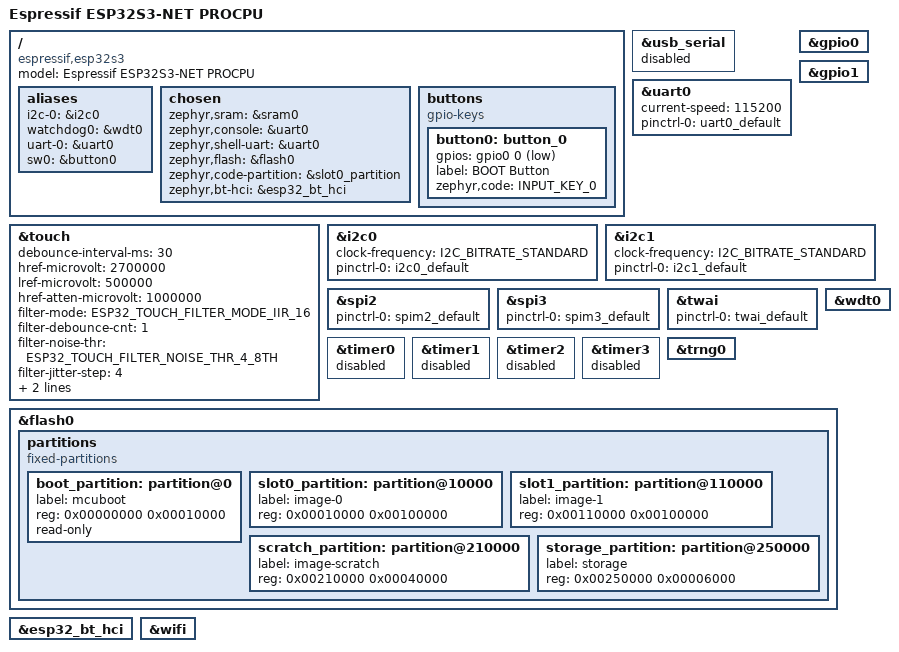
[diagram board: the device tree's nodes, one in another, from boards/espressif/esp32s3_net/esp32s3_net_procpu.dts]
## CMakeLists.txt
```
# SPDX-License-Identifier: Apache-2.0

cmake_minimum_required(VERSION 3.20.0)

list(APPEND BOARD_ROOT ${CMAKE_CURRENT_SOURCE_DIR})
find_package(Zephyr REQUIRED HINTS $ENV{ZEPHYR_BASE})

project(esp32s3_devkitc)

target_sources(app PRIVATE
	src/main.c
	src/wifi.c
	#	src/mqtt.c
	src/http.c
)
```

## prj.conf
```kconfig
CONFIG_LOG=y
CONFIG_LOG_BACKEND_UART=n
CONFIG_LOG_BUFFER_SIZE=2048

CONFIG_SHELL=y
CONFIG_SHELL_BACKEND_SERIAL=y
CONFIG_NET_L2_WIFI_SHELL=y

CONFIG_WIFI=y
CONFIG_WIFI_ESP32=y

CONFIG_NETWORKING=y
CONFIG_NET_L2_ETHERNET=y

CONFIG_NET_IPV6=n
CONFIG_NET_IPV4=y
CONFIG_NET_DHCPV4=y
CONFIG_ESP32_WIFI_STA_AUTO_DHCPV4=y
# 驱动自动重连必须关掉: 断开事件(如首次扫描 NO_AP_FOUND=201)后驱动会把
# 状态锁在 ESP32_STA_CONNECTING 并内部调用 esp_wifi_connect(), 从此应用层
# 所有连接请求都被拒绝(busy -1), 内部重连又静默卡死, 永远无法恢复。
# 关掉后驱动断开即回 ESP32_STA_STARTED, 由 wifi.c 自己的重试循环接管。
CONFIG_ESP32_WIFI_STA_RECONNECT=n
CONFIG_ESP32_WIFI_IRAM_OPT=n
CONFIG_ESP32_WIFI_RX_IRAM_OPT=n

# 网络缓冲池: 数据块必须 ≥1514(一帧一个 buffer), 否则
# 一帧要拆成 12 个 128B 碎片, 而小 RX 池连一个全尺寸帧都装不下,
# 任何 ≥1281B 的单帧(SSDP/mDNS 公告等)到达都必然报
# "Data buffer (1514) allocation failed" 丢帧 —— 不需要突发, 一帧就够
CONFIG_NET_BUF_DATA_SIZE=1600
CONFIG_NET_PKT_RX_COUNT=32
CONFIG_NET_PKT_TX_COUNT=16
CONFIG_NET_BUF_RX_COUNT=32
CONFIG_NET_BUF_TX_COUNT=16
CONFIG_NET_MAX_CONTEXTS=12
CONFIG_NET_MAX_CONN=8
CONFIG_NET_TX_STACK_SIZE=2048
CONFIG_NET_RX_STACK_SIZE=2048
# 防止扫描结果事件丢失
CONFIG_NET_MGMT_EVENT_QUEUE_SIZE=16
CONFIG_NET_MGMT_EVENT_QUEUE_TIMEOUT=5000

CONFIG_NET_LOG=y

# 堆内存大小由板级 Kconfig.defconfig 提供(esp32 wifi 需要 51200),
# 不要在这里设小值, 否则 esp_wifi_start() 内存分配失败


# ===== MQTT Configuration =====
CONFIG_NETWORKING=y
# CONFIG_MQTT_LIB=y

# MQTT 依赖 TCP 传输。Zephyr 3.7 起 NET_TCP 默认关闭且 MQTT_LIB 不会
# 自动 select, 必须显式开启, 否则 socket(SOCK_STREAM) 创建即失败,
# mqtt_connect() 报 -107 (minimal libc 中 EPROTOTYPE=107, 非 Linux 的 ENOTCONN)
CONFIG_NET_TCP=y
CONFIG_NET_SOCKETS=y
CONFIG_DNS_RESOLVER=y

# HTTP 客户端 
CONFIG_HTTP_CLIENT=y
CONFIG_POSIX_API=y
CONFIG_NET_HTTP_LOG_LEVEL_DBG=y
CONFIG_NET_SOCKETS_SOCKOPT_TLS=y
# 1. 启用安全套接字和证书
CONFIG_NET_SOCKETS_SOCKOPT_TLS=y
CONFIG_TLS_CREDENTIALS=y
# 开启 PEM 证书解析
CONFIG_MBEDTLS_PEM_CERTIFICATE_FORMAT=y
# 证书相关
# TLS configuration
CONFIG_MBEDTLS=y
CONFIG_MBEDTLS_BUILTIN=y
# CONFIG_MBEDTLS_ENABLE_HEAP=y
# CONFIG_MBEDTLS_HEAP_SIZE=32768
# 服务器的证书链握手消息约 4758 字节, 超过 4096 时 mbedTLS 3.6 在
# ssl_msg.c 报 "requesting more data than fits" → -0x7100 (BAD_INPUT_DATA)
# 握手失败。8192 足够容纳证书链和后续的响应记录。
CONFIG_MBEDTLS_SSL_MAX_CONTENT_LEN=8192

CONFIG_NET_SOCKETS_SOCKOPT_TLS=y
CONFIG_NET_SOCKETS_TLS_MAX_CONTEXTS=1
# TLS 握手在 zsock_connect() 内完成(Zephyr 3.7), 默认 3s 上限在工地
# 弱网下容易超时, 放宽到 10s
CONFIG_NET_SOCKETS_CONNECT_TIMEOUT=10000

# ========== time ===========
CONFIG_SNTP=y

# =========== PSRAM ===============
# CONFIG_ESP_SPIRAM=y
# CONFIG_SPIRAM_MODE_QUAD=y
# CONFIG_SPIRAM_TYPE_ESPPSRAM16=y
# CONFIG_SPIRAM_SPEED_40M=y
# CONFIG_ESP_SPIRAM_HEAP_SIZE=1048576
# CONFIG_ESP_HEAP_MIN_EXTRAM_THRESHOLD=2048
```

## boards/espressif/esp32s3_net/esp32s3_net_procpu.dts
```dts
/*
 * Copyright (c) 2024 Espressif Systems (Shanghai) Co., Ltd.
 *
 * SPDX-License-Identifier: Apache-2.0
 */
/dts-v1/;

#include "espressif/esp32s3/esp32s3_wroom_n8.dtsi"
#include "esp32s3_net-pinctrl.dtsi"
#include <zephyr/dt-bindings/input/input-event-codes.h>
#include <zephyr/dt-bindings/input/esp32-touch-sensor-input.h>

/ {
	model = "Espressif ESP32S3-NET PROCPU";
	compatible = "espressif,esp32s3";

	aliases {
		i2c-0 = &i2c0;
		watchdog0 = &wdt0;
	};

	chosen {
		zephyr,sram = &sram0;
		zephyr,console = &uart0;
		zephyr,shell-uart = &uart0;
		zephyr,flash = &flash0;
		zephyr,code-partition = &slot0_partition;
		zephyr,bt-hci = &esp32_bt_hci;
	};

	aliases {
		uart-0 = &uart0;
		sw0 = &button0;
	};

	buttons {
		compatible = "gpio-keys";
		button0: button_0 {
			gpios = <&gpio0 0 (GPIO_PULL_UP | GPIO_ACTIVE_LOW)>;
			label = "BOOT Button";
			zephyr,code = <INPUT_KEY_0>;
		};
	};
};

&usb_serial {
	status = "disabled";
};

&uart0 {
	status = "okay";
	current-speed = <115200>;
	pinctrl-0 = <&uart0_default>;
	pinctrl-names = "default";
};

&gpio0 {
	status = "okay";
};

&gpio1 {
	status = "okay";
};

&touch {
	debounce-interval-ms = <30>;
	href-microvolt = <2700000>;
	lref-microvolt = <500000>;
	href-atten-microvolt = <1000000>;
	filter-mode = <ESP32_TOUCH_FILTER_MODE_IIR_16>;
	filter-debounce-cnt = <1>;
	filter-noise-thr = <ESP32_TOUCH_FILTER_NOISE_THR_4_8TH>;
	filter-jitter-step = <4>;
	filter-smooth-level = <ESP32_TOUCH_FILTER_SMOOTH_MODE_IIR_2>;
};

&i2c0 {
	clock-frequency = <I2C_BITRATE_STANDARD>;
	pinctrl-0 = <&i2c0_default>;
	pinctrl-names = "default";
};

&i2c1 {
	clock-frequency = <I2C_BITRATE_STANDARD>;
	pinctrl-0 = <&i2c1_default>;
	pinctrl-names = "default";
};

&spi2 {
	#address-cells = <1>;
	#size-cells = <0>;
	status = "okay";
	pinctrl-0 = <&spim2_default>;
	pinctrl-names = "default";
};

&spi3 {
	#address-cells = <1>;
	#size-cells = <0>;
	status = "okay";
	pinctrl-0 = <&spim3_default>;
	pinctrl-names = "default";
};

&twai {
	pinctrl-0 = <&twai_default>;
	pinctrl-names = "default";
};

&timer0 {
	status = "disabled";
};

&timer1 {
	status = "disabled";
};

&timer2 {
	status = "disabled";
};

&timer3 {
	status = "disabled";
};

&wdt0 {
	status = "okay";
};

&trng0 {
	status = "okay";
};

&flash0 {
	status = "okay";
	partitions {
		compatible = "fixed-partitions";
		#address-cells = <1>;
		#size-cells = <1>;

		/* Reserve 64kB for the bootloader */
		boot_partition: partition@0 {
			label = "mcuboot";
			reg = <0x00000000 0x00010000>;
			read-only;
		};

		/* Reserve 1024kB for the application in slot 0 */
		slot0_partition: partition@10000 {
			label = "image-0";
			reg = <0x00010000 0x00100000>;
		};

		/* Reserve 1024kB for the application in slot 1 */
		slot1_partition: partition@110000 {
			label = "image-1";
			reg = <0x00110000 0x00100000>;
		};

		/* Reserve 256kB for the scratch partition */
		scratch_partition: partition@210000 {
			   label = "image-scratch";
			   reg = <0x00210000 0x00040000>;
		};

		storage_partition: partition@250000 {
			label = "storage";
			reg = <0x00250000 0x00006000>;
		};
	};
};

&esp32_bt_hci {
	status = "okay";
};

&wifi {
	status = "okay";
};
```

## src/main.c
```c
#include <zephyr/kernel.h>
#include <zephyr/logging/log.h>
#include <errno.h>

LOG_MODULE_REGISTER(main, LOG_LEVEL_INF);

int main(void)
{
	LOG_INF("This is a test.");
	while(1) {
		k_msleep(5000);
	}
}
```

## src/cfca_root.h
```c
unsigned char cfca_root_der[] = {
  0x30, 0x82, 0x05, 0x8d, 0x30, 0x82, 0x03, 0x75, 0xa0, 0x03, 0x02, 0x01,
  0x02, 0x02, 0x04, 0x18, 0x4a, 0xcc, 0xd6, 0x30, 0x0d, 0x06, 0x09, 0x2a,
  0x86, 0x48, 0x86, 0xf7, 0x0d, 0x01, 0x01, 0x0b, 0x05, 0x00, 0x30, 0x56,
  0x31, 0x0b, 0x30, 0x09, 0x06, 0x03, 0x55, 0x04, 0x06, 0x13, 0x02, 0x43,
  0x4e, 0x31, 0x30, 0x30, 0x2e, 0x06, 0x03, 0x55, 0x04, 0x0a, 0x0c, 0x27,
  0x43, 0x68, 0x69, 0x6e, 0x61, 0x20, 0x46, 0x69, 0x6e, 0x61, 0x6e, 0x63,
  0x69, 0x61, 0x6c, 0x20, 0x43, 0x65, 0x72, 0x74, 0x69, 0x66, 0x69, 0x63,
  0x61, 0x74, 0x69, 0x6f, 0x6e, 0x20, 0x41, 0x75, 0x74, 0x68, 0x6f, 0x72,
  0x69, 0x74, 0x79, 0x31, 0x15, 0x30, 0x13, 0x06, 0x03, 0x55, 0x04, 0x03,
  0x0c, 0x0c, 0x43, 0x46, 0x43, 0x41, 0x20, 0x45, 0x56, 0x20, 0x52, 0x4f,
  0x4f, 0x54, 0x30, 0x1e, 0x17, 0x0d, 0x31, 0x32, 0x30, 0x38, 0x30, 0x38,
  0x30, 0x33, 0x30, 0x37, 0x30, 0x31, 0x5a, 0x17, 0x0d, 0x32, 0x39, 0x31,
  0x32, 0x33, 0x31, 0x30, 0x33, 0x30, 0x37, 0x30, 0x31, 0x5a, 0x30, 0x56,
  0x31, 0x0b, 0x30, 0x09, 0x06, 0x03, 0x55, 0x04, 0x06, 0x13, 0x02, 0x43,
  0x4e, 0x31, 0x30, 0x30, 0x2e, 0x06, 0x03, 0x55, 0x04, 0x0a, 0x0c, 0x27,
  0x43, 0x68, 0x69, 0x6e, 0x61, 0x20, 0x46, 0x69, 0x6e, 0x61, 0x6e, 0x63,
  0x69, 0x61, 0x6c, 0x20, 0x43, 0x65, 0x72, 0x74, 0x69, 0x66, 0x69, 0x63,
  0x61, 0x74, 0x69, 0x6f, 0x6e, 0x20, 0x41, 0x75, 0x74, 0x68, 0x6f, 0x72,
  0x69, 0x74, 0x79, 0x31, 0x15, 0x30, 0x13, 0x06, 0x03, 0x55, 0x04, 0x03,
  0x0c, 0x0c, 0x43, 0x46, 0x43, 0x41, 0x20, 0x45, 0x56, 0x20, 0x52, 0x4f,
  0x4f, 0x54, 0x30, 0x82, 0x02, 0x22, 0x30, 0x0d, 0x06, 0x09, 0x2a, 0x86,
  0x48, 0x86, 0xf7, 0x0d, 0x01, 0x01, 0x01, 0x05, 0x00, 0x03, 0x82, 0x02,
  0x0f, 0x00, 0x30, 0x82, 0x02, 0x0a, 0x02, 0x82, 0x02, 0x01, 0x00, 0xd7,
  0x5d, 0x6b, 0xcd, 0x10, 0x3f, 0x1f, 0x05, 0x59, 0xd5, 0x05, 0x4d, 0x37,
  0xb1, 0x0e, 0xec, 0x98, 0x2b, 0x8e, 0x15, 0x1d, 0xfa, 0x93, 0x4b, 0x17,
  0x82, 0x21, 0x71, 0x10, 0x52, 0xd7, 0x51, 0x64, 0x70, 0x16, 0xc2, 0x55,
  0x69, 0x4d, 0x8e, 0x15, 0x6d, 0x9f, 0xbf, 0x0c, 0x1b, 0xc2, 0xe0, 0xa3,
  0x67, 0xd6, 0x0c, 0xac, 0xcf, 0x22, 0xae, 0xaf, 0x77, 0x54, 0x2a, 0x4b,
  0x4c, 0x8a, 0x53, 0x52, 0x7a, 0xc3, 0xee, 0x2e, 0xde, 0xb3, 0x71, 0x25,
  0xc1, 0xe9, 0x5d, 0x3d, 0xee, 0xa1, 0x2f, 0xa3, 0xf7, 0x2a, 0x3c, 0xc9,
  0x23, 0x1d, 0x6a, 0xab, 0x1d, 0xa1, 0xa7, 0xf1, 0xf3, 0xec, 0xa0, 0xd5,
  0x44, 0xcf, 0x15, 0xcf, 0x72, 0x2f, 0x1d, 0x63, 0x97, 0xe8, 0x99, 0xf9,
  0xfd, 0x93, 0xa4, 0x54, 0x80, 0x4c, 0x52, 0xd4, 0x52, 0xab, 0x2e, 0x49,
  0xdf, 0x90, 0xcd, 0xb8, 0x5f, 0xbe, 0x3f, 0xde, 0xa1, 0xca, 0x4d, 0x20,
  0xd4, 0x25, 0xe8, 0x84, 0x29, 0x53, 0xb7, 0xb1, 0x88, 0x1f, 0xff, 0xfa,
  0xda, 0x90, 0x9f, 0x0a, 0xa9, 0x2d, 0x41, 0x3f, 0xb1, 0xf1, 0x18, 0x29,
  0xee, 0x16, 0x59, 0x2c, 0x34, 0x49, 0x1a, 0xa8, 0x06, 0xd7, 0xa8, 0x88,
  0xd2, 0x03, 0x72, 0x7a, 0x32, 0xe2, 0xea, 0x68, 0x4d, 0x6e, 0x2c, 0x96,
  0x65, 0x7b, 0xca, 0x59, 0xfa, 0xf2, 0xe2, 0xdd, 0xee, 0x30, 0x2c, 0xfb,
  0xcc, 0x46, 0xac, 0xc4, 0x63, 0xeb, 0x6f, 0x7f, 0x36, 0x2b, 0x34, 0x73,
  0x12, 0x94, 0x7f, 0xdf, 0xcc, 0x26, 0x9e, 0xf1, 0x72, 0x5d, 0x50, 0x65,
  0x59, 0x8f, 0x69, 0xb3, 0x87, 0x5e, 0x32, 0x6f, 0xc3, 0x18, 0x8a, 0xb5,
  0x95, 0x8f, 0xb0, 0x7a, 0x37, 0xde, 0x5a, 0x45, 0x3b, 0xc7, 0x36, 0xe1,
  0xef, 0x67, 0xd1, 0x39, 0xd3, 0x97, 0x5b, 0x73, 0x62, 0x19, 0x48, 0x2d,
  0x87, 0x1c, 0x06, 0xfb, 0x74, 0x98, 0x20, 0x49, 0x73, 0xf0, 0x05, 0xd2,
  0x1b, 0xb1, 0xa0, 0xa3, 0xb7, 0x1b, 0x70, 0xd3, 0x88, 0x69, 0xb9, 0x5a,
  0xd6, 0x38, 0xf4, 0x62, 0xdc, 0x25, 0x8b, 0x78, 0xbf, 0xf8, 0xe8, 0x7e,
  0xb8, 0x5c, 0xc9, 0x95, 0x4f, 0x5f, 0xa7, 0x2d, 0xb9, 0x20, 0x6b, 0xcf,
  0x6b, 0xdd, 0xf5, 0x0d, 0xf4, 0x82, 0xb7, 0xf4, 0xb2, 0x66, 0x2e, 0x10,
  0x28, 0xf6, 0x97, 0x5a, 0x7b, 0x96, 0x16, 0x8f, 0x01, 0x19, 0x2d, 0x6c,
  0x6e, 0x7f, 0x39, 0x58, 0x06, 0x64, 0x83, 0x01, 0x83, 0x83, 0xc3, 0x4d,
  0x92, 0xdd, 0x32, 0xc6, 0x87, 0xa4, 0x37, 0xe9, 0x16, 0xce, 0xaa, 0x2d,
  0x68, 0xaf, 0x0a, 0x81, 0x65, 0x3a, 0x70, 0xc1, 0x9b, 0xad, 0x4d, 0x6d,
  0x54, 0xca, 0x2a, 0x2d, 0x4b, 0x85, 0x1b, 0xb3, 0x80, 0xe6, 0x70, 0x45,
  0x0d, 0x6b, 0x5e, 0x35, 0xf0, 0x7f, 0x3b, 0xb8, 0x9c, 0xe4, 0x04, 0x70,
  0x89, 0x12, 0x25, 0x93, 0xda, 0x0a, 0x99, 0x22, 0x60, 0x6a, 0x63, 0x60,
  0x4e, 0x76, 0x06, 0x98, 0x4e, 0xbd, 0x83, 0xad, 0x1d, 0x58, 0x8a, 0x25,
  0x85, 0xd2, 0xc7, 0x65, 0x1e, 0x2d, 0x8e, 0xc6, 0xdf, 0xb6, 0xc6, 0xe1,
  0x7f, 0x8a, 0x04, 0x21, 0x15, 0x29, 0x74, 0xf0, 0x3e, 0x9c, 0x90, 0x9d,
  0x0c, 0x2e, 0xf1, 0x8a, 0x3e, 0x5a, 0xaa, 0x0c, 0x09, 0x1e, 0xc7, 0xd5,
  0x3c, 0xa3, 0xed, 0x97, 0xc3, 0x1e, 0x34, 0xfa, 0x38, 0xf9, 0x08, 0x0e,
  0xe3, 0xc0, 0x5d, 0x2b, 0x83, 0xd1, 0x56, 0x6a, 0xc9, 0xb6, 0xa8, 0x54,
  0x53, 0x2e, 0x78, 0x32, 0x67, 0x3d, 0x82, 0x7f, 0x74, 0xd0, 0xfb, 0xe1,
  0xb6, 0x05, 0x60, 0xb9, 0x70, 0xdb, 0x8e, 0x0b, 0xf9, 0x13, 0x58, 0x6f,
  0x71, 0x60, 0x10, 0x52, 0x10, 0xb9, 0xc1, 0x41, 0x09, 0xef, 0x72, 0x1f,
  0x67, 0x31, 0x78, 0xff, 0x96, 0x05, 0x8d, 0x02, 0x03, 0x01, 0x00, 0x01,
  0xa3, 0x63, 0x30, 0x61, 0x30, 0x1f, 0x06, 0x03, 0x55, 0x1d, 0x23, 0x04,
  0x18, 0x30, 0x16, 0x80, 0x14, 0xe3, 0xfe, 0x2d, 0xfd, 0x28, 0xd0, 0x0b,
  0xb5, 0xba, 0xb6, 0xa2, 0xc4, 0xbf, 0x06, 0xaa, 0x05, 0x8c, 0x93, 0xfb,
  0x2f, 0x30, 0x0f, 0x06, 0x03, 0x55, 0x1d, 0x13, 0x01, 0x01, 0xff, 0x04,
  0x05, 0x30, 0x03, 0x01, 0x01, 0xff, 0x30, 0x0e, 0x06, 0x03, 0x55, 0x1d,
  0x0f, 0x01, 0x01, 0xff, 0x04, 0x04, 0x03, 0x02, 0x01, 0x06, 0x30, 0x1d,
  0x06, 0x03, 0x55, 0x1d, 0x0e, 0x04, 0x16, 0x04, 0x14, 0xe3, 0xfe, 0x2d,
  0xfd, 0x28, 0xd0, 0x0b, 0xb5, 0xba, 0xb6, 0xa2, 0xc4, 0xbf, 0x06, 0xaa,
  0x05, 0x8c, 0x93, 0xfb, 0x2f, 0x30, 0x0d, 0x06, 0x09, 0x2a, 0x86, 0x48,
  0x86, 0xf7, 0x0d, 0x01, 0x01, 0x0b, 0x05, 0x00, 0x03, 0x82, 0x02, 0x01,
  0x00, 0x25, 0xc6, 0xba, 0x6b, 0xeb, 0x87, 0xcb, 0xde, 0x82, 0x39, 0x96,
  0x3d, 0xf0, 0x44, 0xa7, 0x6b, 0x84, 0x73, 0x03, 0xde, 0x9d, 0x2b, 0x4f,
  0xba, 0x20, 0x7f, 0xbc, 0x78, 0xb2, 0xcf, 0x97, 0xb0, 0x1b, 0x9c, 0xf3,
  0xd7, 0x79, 0x2e, 0xf5, 0x48, 0xb6, 0xd2, 0xfb, 0x17, 0x88, 0xe6, 0xd3,
  0x7a, 0x3f, 0xed, 0x53, 0x13, 0xd0, 0xe2, 0x2f, 0x6a, 0x79, 0xcb, 0x00,
  0x23, 0x28, 0xe6, 0x1e, 0x37, 0x57, 0x35, 0x89, 0x84, 0xc2, 0x76, 0x4f,
  0x34, 0x36, 0xad, 0x67, 0xc3, 0xce, 0x41, 0x06, 0x88, 0xc5, 0xf7, 0xee,
  0xd8, 0x1a, 0xb8, 0xd6, 0x0b, 0x7f, 0x50, 0xff, 0x93, 0xaa, 0x17, 0x4b,
  0x8c, 0xec, 0xed, 0x52, 0x60, 0xb2, 0xa4, 0x06, 0xea, 0x4e, 0xeb, 0xf4,
  0x6b, 0x19, 0xfd, 0xeb, 0xf5, 0x1a, 0xe0, 0x25, 0x2a, 0x9a, 0xdc, 0xc7,
  0x41, 0x36, 0xf7, 0xc8, 0x74, 0x05, 0x84, 0x39, 0x95, 0x39, 0xd6, 0x0b,
  0x3b, 0xa4, 0x27, 0xfa, 0x08, 0xd8, 0x5c, 0x1e, 0xf8, 0x04, 0x60, 0x52,
  0x11, 0x28, 0x28, 0x03, 0xff, 0xef, 0x53, 0x66, 0x00, 0xa5, 0x4a, 0x34,
  0x16, 0x66, 0x7c, 0xfd, 0x09, 0xa4, 0xae, 0x9e, 0x67, 0x1a, 0x6f, 0x41,
  0x0b, 0x6b, 0x06, 0x13, 0x9b, 0x8f, 0x86, 0x71, 0x05, 0xb4, 0x2f, 0x8d,
  0x89, 0x66, 0x33, 0x29, 0x76, 0x54, 0x9a, 0x11, 0xf8, 0x27, 0xfa, 0xb2,
  0x3f, 0x91, 0xe0, 0xce, 0x0d, 0x1b, 0xf3, 0x30, 0x1a, 0xad, 0xbf, 0x22,
  0x5d, 0x1b, 0xd3, 0xbf, 0x25, 0x05, 0x4d, 0xe1, 0x92, 0x1a, 0x7f, 0x99,
  0x9f, 0x3c, 0x44, 0x93, 0xca, 0xd4, 0x40, 0x49, 0x6c, 0x80, 0x87, 0xd7,
  0x04, 0x3a, 0xc3, 0x32, 0x52, 0x35, 0x0e, 0x56, 0xf8, 0xa5, 0xdd, 0x7d,
  0xc4, 0x8b, 0x0d, 0x11, 0x1f, 0x53, 0xcb, 0x1e, 0xb2, 0x17, 0xb6, 0x68,
  0x77, 0x5a, 0xe0, 0xd4, 0xcb, 0xc8, 0x07, 0xae, 0xf5, 0x3a, 0x2e, 0x8e,
  0x37, 0xb7, 0xd0, 0x01, 0x4b, 0x43, 0x29, 0x77, 0x8c, 0x39, 0x97, 0x8f,
  0x82, 0x5a, 0xf8, 0x51, 0xe5, 0x89, 0xa0, 0x18, 0xe7, 0x68, 0x7f, 0x5d,
  0x0a, 0x2e, 0xfb, 0xa3, 0x47, 0x0e, 0x3d, 0xa6, 0x23, 0x7a, 0xc6, 0x01,
  0xc7, 0x8f, 0xc8, 0x5e, 0xbf, 0x6d, 0x80, 0x56, 0xbe, 0x8a, 0x24, 0xba,
  0x33, 0xea, 0x9f, 0xe1, 0x32, 0x11, 0x9e, 0xf1, 0xd2, 0x4f, 0x80, 0xf6,
  0x1b, 0x40, 0xaf, 0x38, 0x9e, 0x11, 0x50, 0x79, 0x73, 0x12, 0x12, 0xcd,
  0xe6, 0x6c, 0x9d, 0x2c, 0x88, 0x72, 0x3c, 0x30, 0x81, 0x06, 0x91, 0x22,
  0xea, 0x59, 0xad, 0xda, 0x19, 0x2e, 0x22, 0xc2, 0x8d, 0xb9, 0x8c, 0x87,
  0xe0, 0x66, 0xbc, 0x73, 0x23, 0x5f, 0x21, 0x64, 0x63, 0x80, 0x48, 0xf5,
  0xa0, 0x3c, 0x18, 0x3d, 0x94, 0xc8, 0x48, 0x41, 0x1d, 0x40, 0xba, 0x5e,
  0xfe, 0xfe, 0x56, 0x39, 0xa1, 0xc8, 0xcf, 0x5e, 0x9e, 0x19, 0x64, 0x46,
  0x10, 0xda, 0x17, 0x91, 0xb7, 0x05, 0x80, 0xac, 0x8b, 0x99, 0x92, 0x7d,
  0xe7, 0xa2, 0xd8, 0x07, 0x0b, 0x36, 0x27, 0xe7, 0x48, 0x79, 0x60, 0x8a,
  0xc3, 0xd7, 0x13, 0x5c, 0xf8, 0x72, 0x40, 0xdf, 0x4a, 0xcb, 0xcf, 0x99,
  0x00, 0x0a, 0x00, 0x0b, 0x11, 0x95, 0xda, 0x56, 0x45, 0x03, 0x88, 0x0a,
  0x9f, 0x67, 0xd0, 0xd5, 0x79, 0xb1, 0xa8, 0x8d, 0x40, 0x6d, 0x0d, 0xc2,
  0x7a, 0x40, 0xfa, 0xf3, 0x5f, 0x64, 0x47, 0x92, 0xcb, 0x53, 0xb9, 0xbb,
  0x59, 0xce, 0x4f, 0xfd, 0xd0, 0x15, 0x53, 0x01, 0xd8, 0xdf, 0xeb, 0xd9,
  0xe6, 0x76, 0xef, 0xd0, 0x23, 0xbb, 0x3b, 0xa9, 0x79, 0xb3, 0xd5, 0x02,
  0x29, 0xcd, 0x89, 0xa3, 0x96, 0x0f, 0x4a, 0x35, 0xe7, 0x4e, 0x42, 0xc0,
  0x75, 0xcd, 0x07, 0xcf, 0xe6, 0x2c, 0xeb, 0x7b, 0x2e
};
unsigned int cfca_root_der_len = 1425;
```

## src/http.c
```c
#include <zephyr/kernel.h>
#include <zephyr/logging/log.h>

// #include <zephyr/posix/sys/socket.h>
// #include <zephyr/posix/unistd.h>
// #include <zephyr/posix/arpa/inet.h>

#include <zephyr/net/net_ip.h>
#include <zephyr/net/net_if.h>
#include <zephyr/net/net_mgmt.h>
#include <zephyr/net/socket.h>
#include <zephyr/net/tls_credentials.h>
#include <zephyr/net/sntp.h>
#include <time.h>
#include <zephyr/net/http/client.h>

#include <zephyr/sys/atomic.h>
#include <string.h>
#include <errno.h>

#include "cfca_root.h"

LOG_MODULE_REGISTER(http, LOG_LEVEL_INF);

#define CA_CERTIFICATE_TAG 	1
#define HTTPS_HOSTNAME 		"jgyw.crfsdi.com.cn"
#define HTTPS_PORT 		"51111"
static const char *extra_headers[] = {
	"Connection: close\r\n",
	"Accept: */*\r\n",
	"User-Agent: Zephyr-HTTP-Client/1.0\r\n",
	NULL
};

static int sockfd = -1;
static uint8_t recv_buf[512];

/* 等待 WiFi + DHCP 拿到 IPv4, 而不是盲睡固定时长:
 * 首次连接含全信道扫描可能 >10s, 网络异常时也要能醒过来报错 */
static atomic_t have_ipv4;
static struct net_mgmt_event_callback ip_cb;

static void ip_event_handler(struct net_mgmt_event_callback *cb,
			     uint32_t mgmt_event, struct net_if *iface)
{
	if (mgmt_event == NET_EVENT_IPV4_ADDR_ADD) {
		atomic_set(&have_ipv4, 1);
	}
}

static bool ipv4_available(void)
{
	struct net_if *iface = net_if_get_default();

	return iface && net_if_ipv4_get_global_addr(iface, NET_ADDR_DHCP) != NULL;
}

static bool network_up(void)
{
	return ipv4_available() || atomic_get(&have_ipv4);
}

static int connect_socket(void) 
{
	struct zsock_addrinfo hints, *res, *p;
	int ret = 0;
	sec_tag_t sec_tag_list[] = { CA_CERTIFICATE_TAG };
	int peer_verify = TLS_PEER_VERIFY_NONE; // 是否难对端证书

	memset(&hints, 0, sizeof(struct zsock_addrinfo));
	hints.ai_family = AF_INET;
	hints.ai_socktype = SOCK_STREAM;

	ret = zsock_getaddrinfo("jgyw.crfsdi.com.cn", "51111", &hints, &res);
	if (ret != 0) {
		LOG_ERR("Get address information failed %d", ret);
		return -1;
	}

	for(p = res; p != NULL; p = p->ai_next) {
		sockfd = zsock_socket(p->ai_family, SOCK_STREAM, IPPROTO_TLS_1_2);
		if (sockfd == -1) {
			LOG_ERR("sockfd get failed %d", sockfd);
			continue;
		}
		
		/* 在 connect 之前设置 tls 选项 */
		/* 设 ca 证书 tag */
		ret = zsock_setsockopt(sockfd, SOL_TLS, TLS_SEC_TAG_LIST, sec_tag_list, sizeof(sec_tag_list));
		if (ret < 0) {
			LOG_ERR("set SEC_TAG_LIST: %s", strerror(errno));
			zsock_close(sockfd);
			sockfd = -1;
			continue;
		}

		/* 设 SNI hostname (通配符证书 *.crfsdi.com.cn 必需) */
		ret = zsock_setsockopt(sockfd, SOL_TLS, TLS_HOSTNAME, HTTPS_HOSTNAME, strlen(HTTPS_HOSTNAME) + 1);
		if (ret < 0) {
			LOG_ERR("set TLS_HOSTNAME: %s", strerror(errno));
			zsock_close(sockfd);
			sockfd = -1;
			continue;
		}

		/* 验证对端证书 */
		ret = zsock_setsockopt(sockfd, SOL_TLS, TLS_PEER_VERIFY,
		       &peer_verify, sizeof(peer_verify));
		if (ret < 0) {
			LOG_ERR("set PEER_VERIFY: %s", strerror(errno));
			zsock_close(sockfd);
			sockfd = -1;
			continue;
		}

		/* 现在 connect ( TLS 握手会在首次 send 时发生 ) */
		ret = zsock_connect(sockfd, p->ai_addr, p->ai_addrlen);
		if (ret != 0) {
			LOG_ERR("Connect socket failed! Code: %d", ret);
			zsock_close(sockfd);
			sockfd = -1;
			continue;
		}
		break;
	
	}
	
	zsock_freeaddrinfo(res);
	if (sockfd == -1) {
		LOG_ERR("All connect failed!");
	}
	return sockfd;
}

static void response_cb(struct http_response *rsp,
			enum http_final_call final_data,
			void *user_data)
{
	if (final_data == HTTP_DATA_MORE) {
		LOG_INF("Partial data received (%zd bytes)", rsp->data_len);
	} else if (final_data == HTTP_DATA_FINAL) {
		LOG_INF("All the data received (%zd bytes)", rsp->data_len);			
	}

	LOG_INF("Response to %s", (const char *)user_data);
	LOG_INF("Response status %s", rsp->http_status);
}

void http_thread_entry(void *a, void *b, void *c)
{
	ARG_UNUSED(a);
	ARG_UNUSED(b);
	ARG_UNUSED(c);

	int ret = 0;
	
	/* 注册 ca 证书, 只需要一次 */
	ret = tls_credential_add(CA_CERTIFICATE_TAG, TLS_CREDENTIAL_CA_CERTIFICATE,
				cfca_root_der,
				cfca_root_der_len);
	if (ret < 0 && ret != -EEXIST) {
		LOG_ERR("tls_credential_add: %d", ret);
		return;
	}
	LOG_INF("CA cert registered.");

	/* 注册 IPV4 事件回调(整个生命周期只注册一次) */
	net_mgmt_init_event_callback(&ip_cb, ip_event_handler,
				     NET_EVENT_IPV4_ADDR_ADD);
	net_mgmt_add_event_callback(&ip_cb);

	struct http_request req = { 0 };
	req.method = HTTP_GET;
	req.url = "/backendapi/auth/publicKey";
	req.host = HTTPS_HOSTNAME;
	req.protocol = "HTTP/1.1";
	req.response = response_cb;
	req.recv_buf = recv_buf;
	req.recv_buf_len = sizeof(recv_buf);
	req.header_fields = extra_headers;

	/* 循环: 等网络 → HTTPS 流程 → 周期重测。
	 * 工地网络可能几分钟后才通, 不能等一次就退出 */
	bool was_up = false;
	int sntp_tries = 0;

	while (1) {
		bool up = network_up();
		if (!up) {
			was_up = false;
			k_sleep(K_SECONDS(2));
			continue;
		}
		if (!was_up) {
			LOG_INF("Network ready (IPv4 acquired)");
			was_up = true;
		}

		/* 尽力同步系统时间(最多试 3 次)。当前
		 * TLS_PEER_VERIFY_NONE 不校验证书, 失败不致命 */
		if (sntp_tries < 3) {
			sntp_tries++;
			struct sntp_time ts;
			int sntp_ret = sntp_simple("120.25.115.20", 15000, &ts);
			if (sntp_ret == 0) {
			    struct timespec now = {
				.tv_sec  = ts.seconds,
				.tv_nsec = ((uint64_t)ts.fraction * 1000000000ULL) >> 32,
			    };
			    clock_settime(CLOCK_REALTIME, &now);
			    LOG_INF("SNTP synced, time=%llu", ts.seconds);
			    sntp_tries = 3; /* 成功即止 */
			} else {
			    LOG_WRN("SNTP failed: %d, continue anyway", sntp_ret);
			}
		}

		/* 弱网下 TLS 握手 + 首次请求可能较慢, 失败重试几次 */
		for (int attempt = 0; attempt < 3; attempt++) {
			/* 连接,内部用IPPROTO_TLS_1_2; Zephyr 3.7 的 TLS 握手
			 * 在 zsock_connect() 内完成 */
			sockfd = connect_socket();
			if (sockfd == -1) {
				LOG_ERR("Connect socket failed (attempt %d)!", attempt + 1);
				k_sleep(K_SECONDS(5));
				continue;
			}
			LOG_INF("Connect socket done!");

			ret = http_client_req(sockfd, &req, 10000, "IPv4 GET");
			if (ret < 0) {
				LOG_ERR("Client error %d (attempt %d)", ret, attempt + 1);
			}

			zsock_close(sockfd);
			sockfd = -1;
			if (ret >= 0) {
				break;
			}
			k_sleep(K_SECONDS(5));
		}

		/* 每 10s 重测一轮; 断网后回到上面的等待 */
		k_sleep(K_SECONDS(10));
	}

}

K_THREAD_DEFINE(myhttp, 8192, http_thread_entry,NULL, NULL, NULL,5, 0, 0);
```

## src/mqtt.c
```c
#include <zephyr/kernel.h>
#include <zephyr/logging/log.h>
#include <zephyr/sys/util.h>

#include <zephyr/net/socket.h>
#include <zephyr/net/mqtt.h>
#include <zephyr/net/net_if.h>
#include <zephyr/net/net_mgmt.h>

#include <zephyr/posix/poll.h>
#include <zephyr/posix/arpa/inet.h>

#include <string.h>
#include <errno.h>

LOG_MODULE_REGISTER(mqtt_sub, LOG_LEVEL_INF);

#define MQTT_THREAD_STACK_SIZE 4096
#define MQTT_THREAD_PRIORITY   5

/* ================= MQTT CONFIG ================= */

#define BROKER_IP       "192.168.1.77"
#define BROKER_PORT     1883

#define CLIENT_ID       "esp32s3_01"

#define SUB_TOPIC       "esp32s2/percent"

#define KEEPALIVE_S     60

/* ================================================= */

static struct mqtt_client client;
static struct sockaddr_storage broker;

static uint8_t rx_buf[512];
static uint8_t tx_buf[512];
/* 载荷必须用独立 buffer: rx_buf 是 MQTT 库的接收缓冲区, 载荷本身
 * 就存在里面, 再往同一个 buffer memcpy 是重叠拷贝, 会损坏载荷 */
static uint8_t payload_buf[256];

static struct pollfd fds[1];

static bool mqtt_connected;

/*
 * Network ready flag
 */
static bool network_ready = false;

static struct net_mgmt_event_callback net_cb;

/*
 * MQTT packet id generator
 */
static atomic_t msg_id = ATOMIC_INIT(0);

static uint16_t mqtt_msg_id(void)
{
	uint16_t id;
	do {
		id = (uint16_t)(atomic_inc(&msg_id) & 0xffff);
	} while (id == 0);

	return id;
}

/*
 * =================================================
 * Network event callback
 * =================================================
 */
static void net_event_handler(struct net_mgmt_event_callback *cb, uint32_t event, struct net_if *iface)
{
	if(event == NET_EVENT_IPV4_ADDR_ADD) {
		LOG_INF("IPv4 address obtained");
		network_ready = true;
	}
}

static void wait_network_ready(void)
{
    	net_mgmt_init_event_callback(&net_cb, net_event_handler, NET_EVENT_IPV4_ADDR_ADD);
    	net_mgmt_add_event_callback(&net_cb);
	LOG_INF("Waiting network...");

    	while(!network_ready) {
        	k_sleep(K_SECONDS(1));
   	}
    	LOG_INF("Network ready");
}

/*
 * Broker address
 */
static int mqtt_broker_init(void)
{
    	struct sockaddr_in *broker4;

	broker4 = (struct sockaddr_in *)&broker;
	memset(&broker,0,sizeof(broker));

	broker4->sin_family = AF_INET;
	broker4->sin_port = htons(BROKER_PORT);
	if(inet_pton(AF_INET, BROKER_IP, &broker4->sin_addr) != 1) {
		LOG_ERR("Invalid broker IP");
		return -EINVAL;
	}
	return 0;
}

/*
 * MQTT subscription
 */
static struct mqtt_topic topics[] =
{
    	{
        	.topic = {
            		.utf8 = (const uint8_t *)SUB_TOPIC,
            		.size = sizeof(SUB_TOPIC)-1,
        	},
        	.qos = MQTT_QOS_0_AT_MOST_ONCE,
    	},
	{
		.topic = {
			.utf8 = (const uint8_t *)"computer/set/led",
			.size = sizeof("computer/set/led") - 1,
		},
		.qos = MQTT_QOS_0_AT_MOST_ONCE,
	}
};


static struct mqtt_subscription_list subscription = {
	.list = topics,
	.list_count = ARRAY_SIZE(topics),
	.message_id = 0,
};

/*
 * MQTT callback
 */
static void mqtt_event_handler(struct mqtt_client *c, const struct mqtt_evt *evt)
{
	int ret;
	switch(evt->type) {
	case MQTT_EVT_CONNACK:
		if(evt->result != 0) {
		    LOG_ERR("CONNACK failed %d", evt->result);
		    mqtt_connected=false;
		    return;
	}
	LOG_INF("MQTT connected");
        mqtt_connected=true;
        subscription.message_id = mqtt_msg_id();
        ret = mqtt_subscribe(c, &subscription);
        if(ret < 0) {
		LOG_ERR("subscribe failed %d", ret);
        }
	break;

    case MQTT_EVT_SUBACK:
	LOG_INF("SUBACK received id=%d", evt->param.suback.message_id);
        break;

    case MQTT_EVT_PUBLISH: {
        const struct mqtt_publish_param *p = &evt->param.publish;
        uint32_t len = p->message.payload.len;
        LOG_INF("MQTT message received.");
        // LOG_INF("topic:%.*s", p->message.topic.topic.size, p->message.topic.topic.utf8);
        if(len < sizeof(payload_buf)) {
		ret = mqtt_readall_publish_payload(c, payload_buf, len);
		if(ret >= 0) {
			payload_buf[len]=0;
			LOG_INF("[topic: %.*s]: %s", p->message.topic.topic.size, p->message.topic.topic.utf8, payload_buf);
		}
	}
	break;
    }

    case MQTT_EVT_DISCONNECT:
	LOG_WRN("MQTT disconnected");
        mqtt_connected=false;
        break;

    default:
        break;
    }
}

/*
 * MQTT thread
 */
static void mqtt_thread(void *a, void *b, void *c)
{
	ARG_UNUSED(a);
	ARG_UNUSED(b);
	ARG_UNUSED(c);

	int ret;
	LOG_INF("MQTT thread start");
	/*
	* 1. wait WiFi + DHCP
	*/
	wait_network_ready();

	/*
	* 2. broker init
	*/
	ret = mqtt_broker_init();

	if(ret < 0) {
		return;
	}

	/*
	* 3. MQTT init
	*/
	mqtt_client_init(&client);

	client.broker = &broker;
	client.evt_cb = mqtt_event_handler;
	client.client_id.utf8 = (uint8_t *)CLIENT_ID;
	client.client_id.size = sizeof(CLIENT_ID)-1;
	client.protocol_version = MQTT_VERSION_3_1_1;
	client.transport.type = MQTT_TRANSPORT_NON_SECURE;
	client.keepalive = KEEPALIVE_S;
	client.rx_buf = rx_buf;
	client.rx_buf_size = sizeof(rx_buf);
	client.tx_buf = tx_buf;
	client.tx_buf_size = sizeof(tx_buf);

	LOG_INF("MQTT client set done.");

	/*
	* 4. connect retry
	*/
	while(1) {
		ret = mqtt_connect(&client);
		if(ret == 0) {
		    LOG_INF("MQTT connect OK");
		    break;
		}
		LOG_ERR("mqtt_connect failed %d", ret);
		k_sleep(K_SECONDS(5));
	}
	/*
	* 5. MQTT loop
	*/
	fds[0].fd = client.transport.tcp.sock;
	fds[0].events = ZSOCK_POLLIN;
	while(1) {
		int timeout;
		timeout = mqtt_keepalive_time_left(&client);
		if(timeout < 0) {
			timeout=1000;
		}

		ret = poll(fds, 1, timeout);

		if(ret > 0) {
		    if(fds[0].revents & ZSOCK_POLLIN) {
			ret = mqtt_input(&client);
			if(ret < 0) {
			    LOG_ERR("mqtt_input error");
			    break;
			}
		    }
		}
		if(mqtt_connected) {
			ret = mqtt_live(&client);
			if(ret < 0 && ret != -EAGAIN) {
				LOG_ERR("mqtt_live error");
				break;
			}
		}
	}
	mqtt_abort(&client);
}


K_THREAD_DEFINE(
        mqtt_tid,
        MQTT_THREAD_STACK_SIZE,
        mqtt_thread,
        NULL,
        NULL,
        NULL,
        MQTT_THREAD_PRIORITY,
        0,
        0);
```

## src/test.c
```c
#include <zephyr/kernel.h>
#include <zephyr/logging/log.h>
#include <zephyr/sys/util.h>

#include <zephyr/net/socket.h>
#include <zephyr/net/net_if.h>
#include <zephyr/net/net_mgmt.h>
#include <zephyr/net/mqtt.h>

#include <zephyr/posix/poll.h>
#include <zephyr/posix/arpa/inet.h>

#include <string.h>
#include <errno.h>

LOG_MODULE_REGISTER(http_client, LOG_LEVEL_INF);

static struct net_mgmt_event_callback net_event_cb_structure;
static struct sockaddr_in broker;
static struct mqtt_client client;

static uint8_t rx_buffer[512];
static uint8_t tx_buffer[512];

static uint8_t payload_buffer[512];

static bool mqtt_connected;
static bool network_ready = false;

static struct pollfd fds[1];

static void net_event_handler(struct net_mgmt_event_callback *cb, uint32_t event, struct net_if *iface)
{
	if (event == NET_EVENT_IPV4_ADDR_ADD) {
		LOG_INF("IPv4 address obtained.");
		network_ready = true;
	}
}

static void wait_network(void) 
{
	net_mgmt_init_event_callback(&net_event_cb_structure, net_event_handler, NET_EVENT_IPV4_ADDR_ADD);
	net_mgmt_add_event_callback(&net_event_cb_structure);
	LOG_INF("Waiting Network...");
	
	while (!network_ready) {
		k_sleep(K_SECONDS(1));
	}
	LOG_INF("Network Ready!");
}

static int broker_init(void) 
{
	int ret = 0;
	broker.sin_family = AF_INET;
	broker.sin_port = htons(1883);
	ret = inet_pton(AF_INET, "192.168.1.77", &broker.sin_addr);
	if (!ret) {
		LOG_ERR("Invalid broker IP");
		return -EINVAL;
	}
	return 0;
}

static atomic_t msg_id = ATOMIC_INIT(0);

static uint16_t generate_mqtt_id(void)
{
	uint16_t id;
	do {
		id = (uint16_t)(atomic_inc(&msg_id) & 0xffff);
	} while (id == 0);	
	
	return id;
}

static struct mqtt_topic topics[] = {
	{
		.topic = {
			.utf8 = (const uint8_t *)"esp32s2/percent",
			.size = sizeof("esp32s2/percent") - 1,
		},
		.qos = MQTT_QOS_0_AT_MOST_ONCE,
	},
	{
		.topic = {
			.utf8 = (const uint8_t *)"topic2",
			.size = sizeof("topic2") - 1,
		},
		.qos = MQTT_QOS_0_AT_MOST_ONCE,
	},
	{
		.topic = {
			.utf8 = (const uint8_t *)"topic3",
			.size = sizeof("topic3") - 1,
		},
		.qos = MQTT_QOS_0_AT_MOST_ONCE,
	},
};  

static struct mqtt_subscription_list subscription = {
	.list = topics,
	.list_count = ARRAY_SIZE(topics),
	.message_id = 0,
};

static void mqtt_event_handler(struct mqtt_client *client, const struct mqtt_evt *evt)
{
	int ret;
	switch (evt->type) {
		case MQTT_EVT_CONNACK: {
			LOG_INF("MQTT waiting ack.");
			if (evt->result) {
				LOG_INF("Ack failed");
				mqtt_connected = false;
				return;
			}
			LOG_INF("MQTT connect successful");
			mqtt_connected = true;
			subscription.message_id = generate_mqtt_id();
			ret = mqtt_subscribe(client, &subscription);
			if (ret < 0) {
				LOG_ERR("subscribe failed: %d", ret);
			}
			break;
		}

		case MQTT_EVT_DISCONNECT: {
			LOG_INF("MQTT Disconnect");
			mqtt_connected = false;
			break;
		}

		case MQTT_EVT_SUBACK: { // Acknowledgment to a subscribe request.
			LOG_INF("Suback received id = %d", evt->param.suback.message_id);
			break;
		}

		case MQTT_EVT_PUBLISH: {
			LOG_INF("MQTT message received.");
			const struct mqtt_publish_param *p = &evt->param.publish;
			uint32_t len = p->message.payload.len;
			if (len < sizeof(payload_buffer)) {
				ret = mqtt_readall_publish_payload(client, payload_buffer, len);	
				if (ret >= 0) {
					payload_buffer[len] = 0;
					LOG_INF("Topic: %.*s ==> %s", p->message.topic.topic.size, p->message.topic.topic.utf8, payload_buffer);
					
				} else {
					LOG_ERR("MQTT read all publish payload failed: %d", ret);
				}
			} else {
				LOG_ERR("Payload is too large: %u >= %zu, dropped", len, sizeof(payload_buffer));
			}
			break;
		}

		default:
			break;
	}
}

static void client_init(struct mqtt_client *c)
{
	mqtt_client_init(c);
	
	c->broker = &broker;
	c->evt_cb = mqtt_event_handler;
	c->client_id.utf8 = (uint8_t *)"esp32_mqtt_client";
	c->client_id.size = sizeof("esp32_mqtt_client") - 1;
	c->password = NULL;
	c->user_name = NULL;
	c->protocol_version = MQTT_VERSION_3_1_1;
	c->transport.type = MQTT_TRANSPORT_NON_SECURE;
	c->rx_buf = rx_buffer;
	c->tx_buf = tx_buffer;
	c->rx_buf_size = sizeof(rx_buffer);
	c->tx_buf_size = sizeof(tx_buffer);
}

static void test_thread_entry(void *arg1, void *arg2, void *arg3)
{
	int ret;
	LOG_INF("test thread started.");	

	wait_network();
	broker_init();
	client_init(&client);

	while (1) {
		ret = mqtt_connect(&client);
		if (ret == 0) {
			LOG_INF("MQTT connect done");
			break;
		}
		LOG_ERR("MQTT connect failed");
		mqtt_abort(&client);
		k_sleep(K_SECONDS(1));
	}

	fds[0].fd = client.transport.tcp.sock;
	fds[0].events = ZSOCK_POLLIN;
	
	
	while (1) {
		int timeout = mqtt_keepalive_time_left(&client);
		if (timeout < 0) 
			timeout = 1000;

		ret = poll(fds, 1, timeout);
		
		if (ret < 0) {
			LOG_ERR("Poll error: %d", errno);
			break;
		}
		if (ret > 0 && (fds[0].revents & ZSOCK_POLLIN)) {
			ret = mqtt_input(&client);
			if (ret < 0) {
				LOG_ERR("mqtt input error");
				break;
			}
		}
		
		
		if (mqtt_connected) {
			ret = mqtt_live(&client);
			if (ret < 0 && ret != -EAGAIN) {
				LOG_ERR("mqtt live error");
				break;
			}
		}
	}

	mqtt_abort(&client);
}

K_THREAD_DEFINE(test, 4096, test_thread_entry, NULL, NULL, NULL, 5, 0, 0);
```

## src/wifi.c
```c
#include <zephyr/kernel.h>
#include <zephyr/sys/atomic.h>
#include <zephyr/net/wifi_mgmt.h>
#include <zephyr/logging/log.h>

LOG_MODULE_REGISTER(wifi, LOG_LEVEL_INF);

#define WIFI_THREAD_STACK_SIZE 4096
#define WIFI_THREAD_PRIORITY 5
#define SSID "QHDTUC2.4"
#define PASSWORD "QHDTUC11305610"

/* 连接结果信号量: 成功/失败/掉线事件都会 give, 唤醒 wifi 线程 */
static K_SEM_DEFINE(wifi_event_sem, 0, 1);
/* 跨线程(回调上下文 vs wifi 线程)共享的状态, 必须用原子操作 */
static atomic_t wifi_connected;
/* 注意: net_mgmt 派发时按 LAYER 位精确匹配回调的事件掩码,
 * WIFI 事件是 L2 层、IPV4 事件是 L3 层, 混在同一个掩码里会导致
 * 两个层的事件都匹配不上, 回调永远不被调用 —— 必须分开注册 */
static struct net_mgmt_event_callback wifi_mgmt_cb;
static struct net_mgmt_event_callback ipv4_mgmt_cb;

static struct wifi_connect_req_params params = {
	.ssid        = SSID,
	.ssid_length = sizeof(SSID) - 1,
	.psk         = PASSWORD,
	.psk_length  = sizeof(PASSWORD) - 1,
	.channel     = 0,
	.security    = WIFI_SECURITY_TYPE_PSK,
	.band        = WIFI_FREQ_BAND_2_4_GHZ,
	.mfp         = WIFI_MFP_DISABLE,
};

static void wifi_event_handler(struct net_mgmt_event_callback *cb,
			       uint32_t mgmt_event, struct net_if *iface)
{
	const struct wifi_status *status = (const struct wifi_status *)cb->info;

	if (mgmt_event == NET_EVENT_WIFI_CONNECT_RESULT) {
		if (status->status) {
			if (status->status == -1) {
				/* 驱动处于 CONNECTING/已连接时 raise 的"假失败"
				 * (esp_wifi_drv.c esp32_wifi_connect): 驱动状态
				 * 并未改变, 不能清 wifi_connected, 也不给信号量,
				 * 让 wifi 线程继续等真正的连接/断开结果事件 */
				LOG_INF("wifi connect busy (-1), ignore");
				return;
			}
			LOG_ERR("wifi connect failed %d", status->status);
			atomic_set(&wifi_connected, 0);
		} else {
			LOG_INF("wifi connected");
			atomic_set(&wifi_connected, 1);
		}
		k_sem_give(&wifi_event_sem);
	} else if (mgmt_event == NET_EVENT_WIFI_DISCONNECT_RESULT) {
		LOG_WRN("wifi disconnected");
		atomic_set(&wifi_connected, 0);
		k_sem_give(&wifi_event_sem);
	}
}

static void ipv4_event_handler(struct net_mgmt_event_callback *cb,
			       uint32_t mgmt_event, struct net_if *iface)
{
	if (mgmt_event == NET_EVENT_IPV4_ADDR_ADD) {
		/* CONFIG_ESP32_WIFI_STA_AUTO_DHCPV4=y 时驱动连接成功后只启动
		 * DHCP, 不 raise CONNECT_RESULT(见 esp_wifi_drv.c 的
		 * esp_wifi_handle_sta_connect_event), 所以真正"可通信"的标志
		 * 是 DHCP 拿到 IPv4 地址 */
		LOG_INF("wifi connected (IPv4 acquired)");
		atomic_set(&wifi_connected, 1);
		k_sem_give(&wifi_event_sem);
	} else if (mgmt_event == NET_EVENT_IPV4_ADDR_DEL) {
		LOG_WRN("wifi IPv4 address lost");
		atomic_set(&wifi_connected, 0);
		k_sem_give(&wifi_event_sem);
	}
}

/* 每次调用都重新取 iface, 取不到返回 -ENODEV 由上层退避重试 */
static int wifi_connect_once(void)
{
	struct net_if *iface = net_if_get_default();

	// k_msleep(2000);
	if (!iface) {
		return -ENODEV;
	}

	return net_mgmt(NET_REQUEST_WIFI_CONNECT, iface,
			&params, sizeof(params));
}

static void wifi_thread_entry(void *a, void *b, void *c)
{
	ARG_UNUSED(a);
	ARG_UNUSED(b);
	ARG_UNUSED(c);

	net_mgmt_init_event_callback(&wifi_mgmt_cb, wifi_event_handler,
		NET_EVENT_WIFI_CONNECT_RESULT | NET_EVENT_WIFI_DISCONNECT_RESULT);
	net_mgmt_add_event_callback(&wifi_mgmt_cb);

	net_mgmt_init_event_callback(&ipv4_mgmt_cb, ipv4_event_handler,
		NET_EVENT_IPV4_ADDR_ADD | NET_EVENT_IPV4_ADDR_DEL);
	net_mgmt_add_event_callback(&ipv4_mgmt_cb);

	/* 上电后先等驱动/PHY 稳定再发起首次连接:
	 * 否则第一次连接大概率以 WIFI_REASON_TIMEOUT(39) 失败 */
	k_sleep(K_SECONDS(5));

	while (1) {
		if (atomic_get(&wifi_connected)) {
			/* 已连接: 阻塞等掉线事件 */
			k_sem_take(&wifi_event_sem, K_FOREVER);
			/* 掉线后稍等, 给驱动内部自动重连留时间 */
			k_sleep(K_SECONDS(2));
		} else {
			k_sleep(K_SECONDS(2));
			int ret = wifi_connect_once();
			LOG_INF("wifi connecting...");

			if (ret == 0) {
				/* 请求已提交, 等结果事件; 带超时是防止事件丢失后
				 * 永远卡住. 首次连接含全信道扫描, 实测 >10s,
				 * 超时给足 15s */
				k_sem_take(&wifi_event_sem, K_SECONDS(15));
			} else if (ret == -EALREADY) {
				/* 驱动已经在连接中, 别急着重试, 耐心等 */
				k_sleep(K_SECONDS(5));
			} else {
				LOG_WRN("connect request failed (%d), retrying...", ret);
				k_sleep(K_SECONDS(1));
			}
		}
	}
}

K_THREAD_DEFINE(wifi_thread, WIFI_THREAD_STACK_SIZE, wifi_thread_entry,
		NULL, NULL, NULL, WIFI_THREAD_PRIORITY, 0, 0);
```
